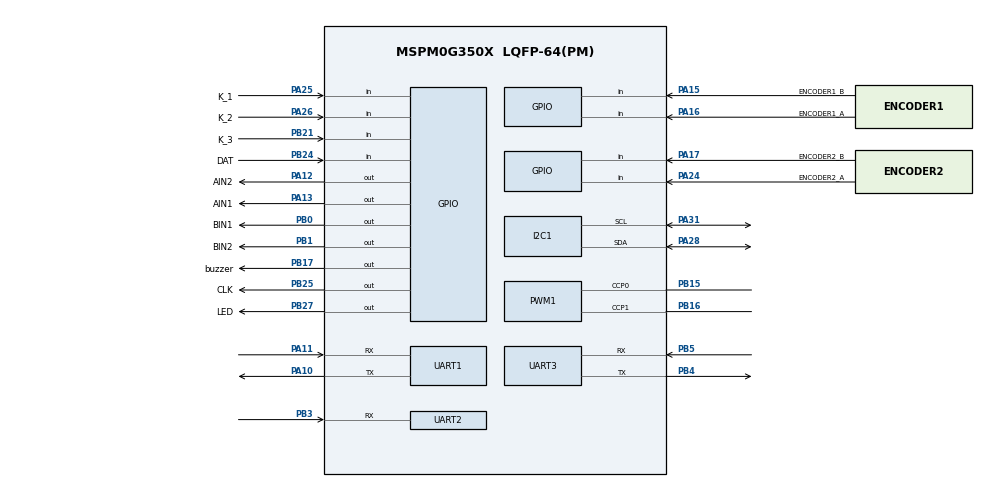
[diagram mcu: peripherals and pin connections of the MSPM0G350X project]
/**
 * @cliArgs --device "MSPM0G350X" --part "Default" --package "LQFP-64(PM)" --product "mspm0_sdk@2.11.00.07"
 * @versions {"tool":"1.26.2+4477"}
 */

/**
 * Import the modules used in this configuration.
 */
const GPIO    = scripting.addModule("/ti/driverlib/GPIO", {}, false);
const GPIO1   = GPIO.addInstance();
const GPIO2   = GPIO.addInstance();
const GPIO3   = GPIO.addInstance();
const GPIO4   = GPIO.addInstance();
const GPIO5   = GPIO.addInstance();
const I2C     = scripting.addModule("/ti/driverlib/I2C", {}, false);
const I2C1    = I2C.addInstance();
const PWM     = scripting.addModule("/ti/driverlib/PWM", {}, false);
const PWM1    = PWM.addInstance();
const SYSCTL  = scripting.addModule("/ti/driverlib/SYSCTL");
const SYSTICK = scripting.addModule("/ti/driverlib/SYSTICK");
const TIMER   = scripting.addModule("/ti/driverlib/TIMER", {}, false);
const TIMER1  = TIMER.addInstance();
const UART    = scripting.addModule("/ti/driverlib/UART", {}, false);
const UART1   = UART.addInstance();
const UART2   = UART.addInstance();
const UART3   = UART.addInstance();

/**
 * Write custom configuration values to the imported modules.
 */
const divider9       = system.clockTree["UDIV"];
divider9.divideValue = 2;

const multiplier2         = system.clockTree["PLL_QDIV"];
multiplier2.multiplyValue = 5;

const mux8       = system.clockTree["HSCLKMUX"];
mux8.inputSelect = "HSCLKMUX_SYSPLL0";

GPIO1.$name                          = "LIGHT";
GPIO1.associatedPins[0].$name        = "LED";
GPIO1.associatedPins[0].initialValue = "SET";
GPIO1.associatedPins[0].pin.$assign  = "PB27";

const Board = scripting.addModule("/ti/driverlib/Board", {}, false);

GPIO2.$name                         = "BUZZER";
GPIO2.associatedPins[0].$name       = "buzzer";
GPIO2.associatedPins[0].pin.$assign = "PB17";

GPIO3.$name                              = "KEY";
GPIO3.associatedPins.create(3);
GPIO3.associatedPins[0].$name            = "K_1";
GPIO3.associatedPins[0].direction        = "INPUT";
GPIO3.associatedPins[0].interruptEn      = true;
GPIO3.associatedPins[0].polarity         = "FALL";
GPIO3.associatedPins[0].internalResistor = "PULL_UP";
GPIO3.associatedPins[0].pin.$assign      = "PA25";
GPIO3.associatedPins[1].$name            = "K_2";
GPIO3.associatedPins[1].direction        = "INPUT";
GPIO3.associatedPins[1].interruptEn      = true;
GPIO3.associatedPins[1].polarity         = "FALL";
GPIO3.associatedPins[1].internalResistor = "PULL_UP";
GPIO3.associatedPins[1].pin.$assign      = "PA26";
GPIO3.associatedPins[2].$name            = "K_3";
GPIO3.associatedPins[2].direction        = "INPUT";
GPIO3.associatedPins[2].internalResistor = "PULL_UP";
GPIO3.associatedPins[2].interruptEn      = true;
GPIO3.associatedPins[2].polarity         = "FALL";
GPIO3.associatedPins[2].pin.$assign      = "PB21";

GPIO4.$name                              = "DC_MOTOR";
GPIO4.associatedPins.create(8);
GPIO4.associatedPins[0].$name            = "AIN1";
GPIO4.associatedPins[0].pin.$assign      = "PA13";
GPIO4.associatedPins[1].$name            = "AIN2";
GPIO4.associatedPins[1].pin.$assign      = "PA12";
GPIO4.associatedPins[2].$name            = "BIN1";
GPIO4.associatedPins[2].pin.$assign      = "PB0";
GPIO4.associatedPins[3].$name            = "BIN2";
GPIO4.associatedPins[3].pin.$assign      = "PB1";
GPIO4.associatedPins[4].$name            = "ENCODER1_A";
GPIO4.associatedPins[4].direction        = "INPUT";
GPIO4.associatedPins[4].internalResistor = "PULL_DOWN";
GPIO4.associatedPins[4].interruptEn      = true;
GPIO4.associatedPins[4].polarity         = "RISE";
GPIO4.associatedPins[4].pin.$assign      = "PA16";
GPIO4.associatedPins[5].$name            = "ENCODER1_B";
GPIO4.associatedPins[5].direction        = "INPUT";
GPIO4.associatedPins[5].internalResistor = "PULL_DOWN";
GPIO4.associatedPins[5].interruptEn      = true;
GPIO4.associatedPins[5].polarity         = "RISE";
GPIO4.associatedPins[5].pin.$assign      = "PA15";
GPIO4.associatedPins[6].$name            = "ENCODER2_A";
GPIO4.associatedPins[6].direction        = "INPUT";
GPIO4.associatedPins[6].internalResistor = "PULL_DOWN";
GPIO4.associatedPins[6].interruptEn      = true;
GPIO4.associatedPins[6].polarity         = "RISE";
GPIO4.associatedPins[6].pin.$assign      = "PA24";
GPIO4.associatedPins[7].$name            = "ENCODER2_B";
GPIO4.associatedPins[7].direction        = "INPUT";
GPIO4.associatedPins[7].internalResistor = "PULL_DOWN";
GPIO4.associatedPins[7].interruptEn      = true;
GPIO4.associatedPins[7].polarity         = "RISE";
GPIO4.associatedPins[7].pin.$assign      = "PA17";

GPIO5.$name                         = "GW_Serial";
GPIO5.associatedPins.create(2);
GPIO5.associatedPins[0].$name       = "DAT";
GPIO5.associatedPins[0].direction   = "INPUT";
GPIO5.associatedPins[0].pin.$assign = "PB24";
GPIO5.associatedPins[1].$name       = "CLK";
GPIO5.associatedPins[1].pin.$assign = "PB25";

I2C1.$name                             = "I2C_OLED";
I2C1.basicEnableController             = true;
I2C1.basicControllerStandardBusSpeed   = "Fast";
I2C1.peripheral.$assign                = "I2C0";
I2C1.peripheral.sdaPin.$assign         = "PA28";
I2C1.peripheral.sclPin.$assign         = "PA31";
I2C1.sdaPinConfig.$name                = "ti_driverlib_gpio_GPIOPinGeneric0";
I2C1.sdaPinConfig.hideOutputInversion  = scripting.forceWrite(false);
I2C1.sdaPinConfig.onlyInternalResistor = scripting.forceWrite(false);
I2C1.sdaPinConfig.passedPeripheralType = scripting.forceWrite("Digital");
I2C1.sclPinConfig.$name                = "ti_driverlib_gpio_GPIOPinGeneric1";
I2C1.sclPinConfig.hideOutputInversion  = scripting.forceWrite(false);
I2C1.sclPinConfig.onlyInternalResistor = scripting.forceWrite(false);
I2C1.sclPinConfig.passedPeripheralType = scripting.forceWrite("Digital");

PWM1.$name                              = "PWM_MOTOR";
PWM1.clockDivider                       = 2;
PWM1.timerCount                         = 4000;
PWM1.timerStartTimer                    = true;
PWM1.pwmMode                            = "EDGE_ALIGN_UP";
PWM1.peripheral.$assign                 = "TIMG7";
PWM1.peripheral.ccp0Pin.$assign         = "PB15";
PWM1.peripheral.ccp1Pin.$assign         = "PB16";
PWM1.PWM_CHANNEL_0.$name                = "ti_driverlib_pwm_PWMTimerCC0";
PWM1.PWM_CHANNEL_1.$name                = "ti_driverlib_pwm_PWMTimerCC1";
PWM1.ccp0PinConfig.$name                = "ti_driverlib_gpio_GPIOPinGeneric2";
PWM1.ccp0PinConfig.direction            = scripting.forceWrite("OUTPUT");
PWM1.ccp0PinConfig.hideOutputInversion  = scripting.forceWrite(false);
PWM1.ccp0PinConfig.onlyInternalResistor = scripting.forceWrite(false);
PWM1.ccp0PinConfig.passedPeripheralType = scripting.forceWrite("Digital");
PWM1.ccp1PinConfig.$name                = "ti_driverlib_gpio_GPIOPinGeneric3";
PWM1.ccp1PinConfig.direction            = scripting.forceWrite("OUTPUT");
PWM1.ccp1PinConfig.hideOutputInversion  = scripting.forceWrite(false);
PWM1.ccp1PinConfig.onlyInternalResistor = scripting.forceWrite(false);
PWM1.ccp1PinConfig.passedPeripheralType = scripting.forceWrite("Digital");

SYSCTL.forceDefaultClkConfig = true;
SYSCTL.clockTreeEn           = true;

SYSTICK.periodEnable      = true;
SYSTICK.interruptEnable   = true;
SYSTICK.interruptPriority = "0";
SYSTICK.systickEnable     = true;
SYSTICK.period            = 80000;

TIMER1.$name              = "MOTOR_CONTROL";
TIMER1.timerClkPrescale   = 100;
TIMER1.timerPeriod        = "50 ms";
TIMER1.timerStartTimer    = true;
TIMER1.interrupts         = ["LOAD"];
TIMER1.timerMode          = "PERIODIC_UP";
TIMER1.peripheral.$assign = "TIMG6";

UART1.$name                            = "DEBUG";
UART1.targetBaudRate                   = 115200;
UART1.peripheral.rxPin.$assign         = "PA11";
UART1.peripheral.txPin.$assign         = "PA10";
UART1.txPinConfig.$name                = "ti_driverlib_gpio_GPIOPinGeneric4";
UART1.txPinConfig.direction            = scripting.forceWrite("OUTPUT");
UART1.txPinConfig.hideOutputInversion  = scripting.forceWrite(false);
UART1.txPinConfig.onlyInternalResistor = scripting.forceWrite(false);
UART1.txPinConfig.passedPeripheralType = scripting.forceWrite("Digital");
UART1.rxPinConfig.$name                = "ti_driverlib_gpio_GPIOPinGeneric5";
UART1.rxPinConfig.hideOutputInversion  = scripting.forceWrite(false);
UART1.rxPinConfig.onlyInternalResistor = scripting.forceWrite(false);
UART1.rxPinConfig.passedPeripheralType = scripting.forceWrite("Digital");

UART2.$name                            = "UART_WIT";
UART2.targetBaudRate                   = 115200;
UART2.direction                        = "RX";
UART2.enableFIFO                       = true;
UART2.enabledInterrupts                = ["RX_TIMEOUT_ERROR"];
UART2.rxTimeoutValue                   = 1;
UART2.enabledDMARXTriggers             = "DL_UART_DMA_INTERRUPT_RX";
UART2.rxPinConfig.$name                = "ti_driverlib_gpio_GPIOPinGeneric7";
UART2.rxPinConfig.hideOutputInversion  = scripting.forceWrite(false);
UART2.rxPinConfig.onlyInternalResistor = scripting.forceWrite(false);
UART2.rxPinConfig.passedPeripheralType = scripting.forceWrite("Digital");
UART2.peripheral.rxPin.$assign         = "PB3";
UART2.DMA_CHANNEL_RX.$name             = "DMA_WIT";
UART2.DMA_CHANNEL_RX.addressMode       = "f2b";
UART2.DMA_CHANNEL_RX.srcLength         = "BYTE";
UART2.DMA_CHANNEL_RX.dstLength         = "BYTE";

UART3.$name                            = "UART_TRANS";
UART3.enabledInterrupts                = ["RX"];
UART3.targetBaudRate                   = 115200;
UART3.peripheral.rxPin.$assign         = "PB5";
UART3.peripheral.txPin.$assign         = "PB4";
UART3.txPinConfig.$name                = "ti_driverlib_gpio_GPIOPinGeneric6";
UART3.txPinConfig.direction            = scripting.forceWrite("OUTPUT");
UART3.txPinConfig.hideOutputInversion  = scripting.forceWrite(false);
UART3.txPinConfig.onlyInternalResistor = scripting.forceWrite(false);
UART3.txPinConfig.passedPeripheralType = scripting.forceWrite("Digital");
UART3.rxPinConfig.$name                = "ti_driverlib_gpio_GPIOPinGeneric8";
UART3.rxPinConfig.hideOutputInversion  = scripting.forceWrite(false);
UART3.rxPinConfig.onlyInternalResistor = scripting.forceWrite(false);
UART3.rxPinConfig.passedPeripheralType = scripting.forceWrite("Digital");

/**
 * Pinmux solution for unlocked pins/peripherals. This ensures that minor changes to the automatic solver in a future
 * version of the tool will not impact the pinmux you originally saw.  These lines can be completely deleted in order to
 * re-solve from scratch.
 */
Board.peripheral.$suggestSolution                = "DEBUGSS";
Board.peripheral.swclkPin.$suggestSolution       = "PA20";
Board.peripheral.swdioPin.$suggestSolution       = "PA19";
UART1.peripheral.$suggestSolution                = "UART0";
UART2.peripheral.$suggestSolution                = "UART3";
UART2.DMA_CHANNEL_RX.peripheral.$suggestSolution = "DMA_CH0";
UART3.peripheral.$suggestSolution                = "UART1";
